# XHSC_HC32L19X register map
Vendor: XHSC Co.Ltd; Series: ARMCM0P; File version: 1.2
CPU: CM0 r0p0, little endian, no MPU, no FPU, 3 interrupt priority bits
Registers are 32-bit, read-write, reset 0x0 unless marked. A register's access mark holds for its fields unless they carry their own. Offsets are from the block's base; [hi:lo] are bit positions; {n}, {i} and the like mark numbered series; 'fields as' and 'values as' point back to an identical list.

## AES
Base 0x40021400
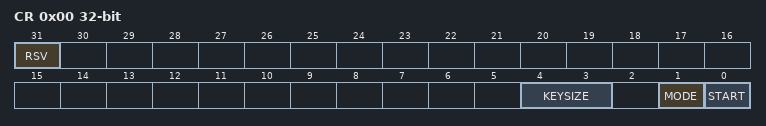
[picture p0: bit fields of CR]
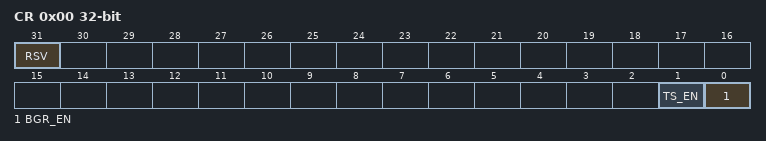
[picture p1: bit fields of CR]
0x00 CR (reset mask 0x3)
  [31] RSV, [4:3] KEYSIZE, [1] MODE, [0] START
0x10 DATA0
{0x10+4i} DATA{i} (i=1..3)
  [31:0] DATA0
0x20 KEY0
{0x20+4i} KEY{i} (i=1..7)
  [31:0] KEY0

## BGR
Base 0x40002400; alternate view of ADC
0x00 CR (reset mask 0x3)
  [31] RSV, [1] TS_EN, [0] BGR_EN

## CLK_TRIM
Base 0x40001800
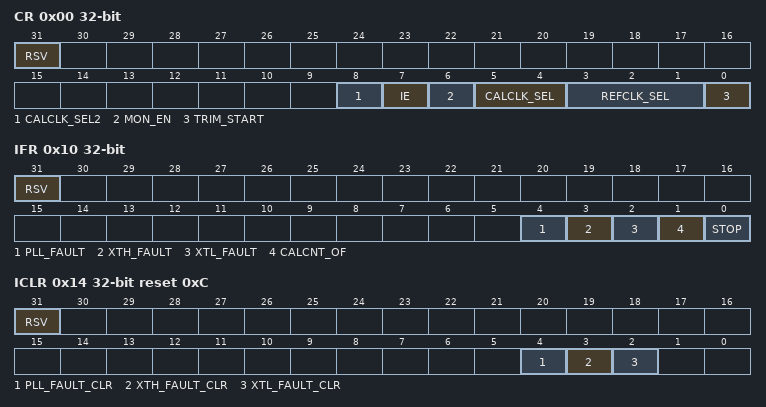
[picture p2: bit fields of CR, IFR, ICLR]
0x00 CR (reset mask 0xFF)
  [31] RSV, [8] CALCLK_SEL2, [7] IE, [6] MON_EN, [5:4] CALCLK_SEL, [3:1] REFCLK_SEL, [0] TRIM_START
0x04 REFCON
  [31:0] RCNTVAL
0x08 REFCNT ro
0x0C CALCNT ro
0x10 IFR ro (reset mask 0xF)
  [31] RSV, [4] PLL_FAULT, [3] XTH_FAULT, [2] XTL_FAULT, [1] CALCNT_OF, [0] STOP
0x14 ICLR reset 0xC (reset mask 0xC)
  [31] RSV, [4] PLL_FAULT_CLR, [3] XTH_FAULT_CLR, [2] XTL_FAULT_CLR
0x18 CALCON reset 0xFFFFFFFF
  [31:0] CCNTVAL

## CRC
Base 0x40020900
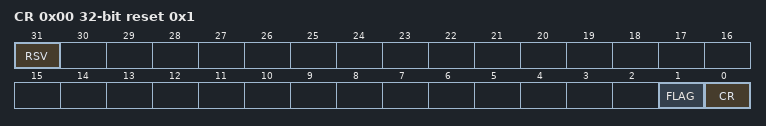
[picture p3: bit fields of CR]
0x00 CR reset 0x1 (reset mask 0x3)
  [31] RSV ro, [1] FLAG ro, [0] CR
0x04 RESULT
0x80 DATA wo

## DAC
Base 0x40002500
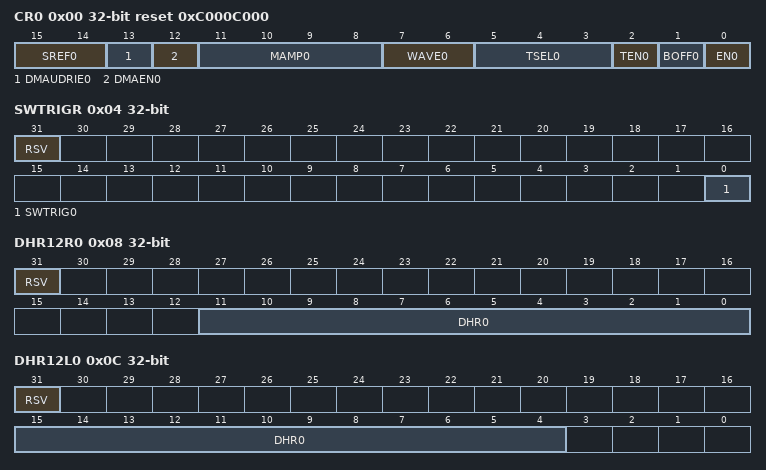
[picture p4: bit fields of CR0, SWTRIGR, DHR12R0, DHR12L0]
0x00 CR0 reset 0xC000C000
  [15:14] SREF0, [13] DMAUDRIE0, [12] DMAEN0, [11:8] MAMP0, [7:6] WAVE0, [5:3] TSEL0, [2] TEN0, [1] BOFF0, [0] EN0
0x04 SWTRIGR wo (reset mask 0x3)
  [31] RSV rw, [0] SWTRIG0
0x08 DHR12R0 (reset mask 0xFFF)
  [31] RSV, [11:0] DHR0
0x0C DHR12L0 (reset mask 0xFFF0)
  [31] RSV, [15:4] DHR0
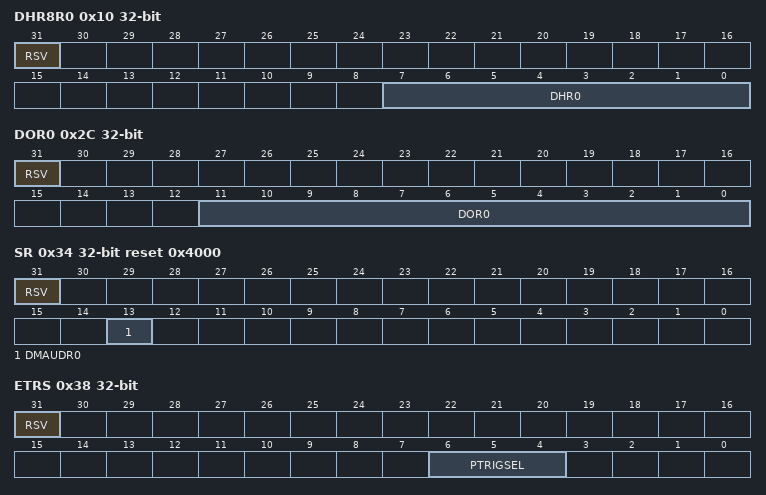
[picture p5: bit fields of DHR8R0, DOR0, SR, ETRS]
0x10 DHR8R0 (reset mask 0xFF)
  [31] RSV, [7:0] DHR0
0x2C DOR0 ro (reset mask 0xFFF)
  [31] RSV rw, [11:0] DOR0
0x34 SR reset 0x4000 (reset mask 0x20002000)
  [31] RSV, [13] DMAUDR0
0x38 ETRS (reset mask 0x70)
  [31] RSV, [6:4] PTRIGSEL

## DEBUG_ACTIVE
Base 0x40002038
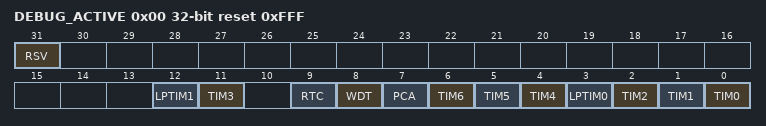
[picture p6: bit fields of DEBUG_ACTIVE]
0x00 DEBUG_ACTIVE reset 0xFFF (reset mask 0xFFF)
  [31] RSV, [12] LPTIM1, [11] TIM3, [9] RTC, [8] WDT, [7] PCA, [6] TIM6, [5] TIM5, [4] TIM4, [3] LPTIM0, [2] TIM2, [1] TIM1, [0] TIM0

## DMAC
Base 0x40021000
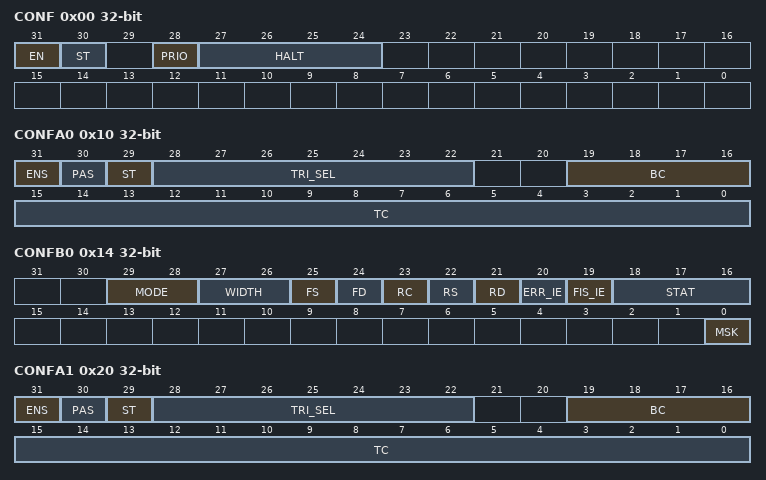
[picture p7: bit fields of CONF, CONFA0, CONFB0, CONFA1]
0x00 CONF
  [31] EN, [30] ST, [28] PRIO, [27:24] HALT
0x10 CONFA0 (reset mask 0xFF8FFFFF)
  [31] ENS, [30] PAS, [29] ST, [28:22] TRI_SEL, [19:16] BC, [15:0] TC
0x14 CONFB0
  [29:28] MODE, [27:26] WIDTH, [25] FS, [24] FD, [23] RC, [22] RS, [21] RD, [20] ERR_IE, [19] FIS_IE, [18:16] STAT, [0] MSK
0x18 SRCADR0
  [31:0] SRCADR
0x1C DSTADR0
  [31:0] DSTADR
0x20 CONFA1 (reset mask 0xFF8FFFFF)
  [31] ENS, [30] PAS, [29] ST, [28:22] TRI_SEL, [19:16] BC, [15:0] TC
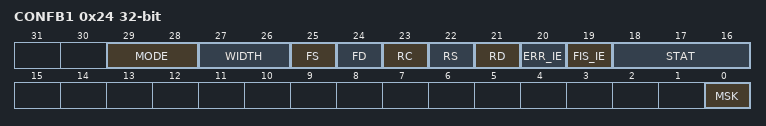
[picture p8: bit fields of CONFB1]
0x24 CONFB1
  fields as CONFB0
0x28 SRCADR1
  [31:0] SRCADR
0x2C DSTADR1
  [31:0] DSTADR

## FLASH
Base 0x40020000
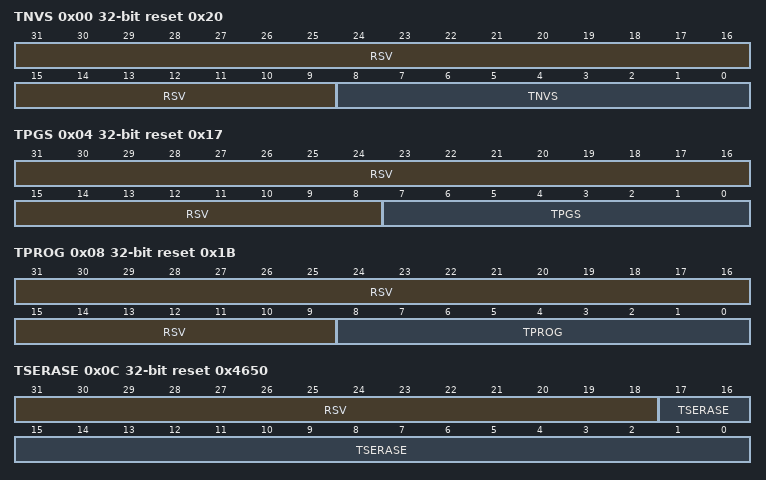
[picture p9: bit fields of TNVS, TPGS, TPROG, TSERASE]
0x00 TNVS reset 0x20 (reset mask 0x1FF)
  [31:9] RSV, [8:0] TNVS
0x04 TPGS reset 0x17 (reset mask 0xFF)
  [31:8] RSV, [7:0] TPGS
0x08 TPROG reset 0x1B (reset mask 0xFF)
  [31:9] RSV, [8:0] TPROG
0x0C TSERASE reset 0x4650 (reset mask 0x3FFFF)
  [31:18] RSV, [17:0] TSERASE
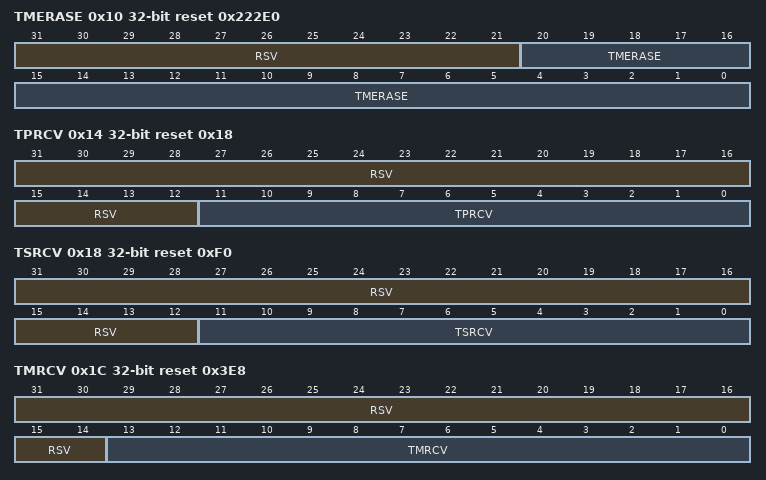
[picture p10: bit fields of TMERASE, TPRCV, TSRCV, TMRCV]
0x10 TMERASE reset 0x222E0 (reset mask 0x1FFFFF)
  [31:21] RSV, [20:0] TMERASE
0x14 TPRCV reset 0x18 (reset mask 0xFFF)
  [31:12] RSV, [11:0] TPRCV
0x18 TSRCV reset 0xF0 (reset mask 0xFFF)
  [31:12] RSV, [11:0] TSRCV
0x1C TMRCV reset 0x3E8 (reset mask 0x1FFF)
  [31:14] RSV, [13:0] TMRCV
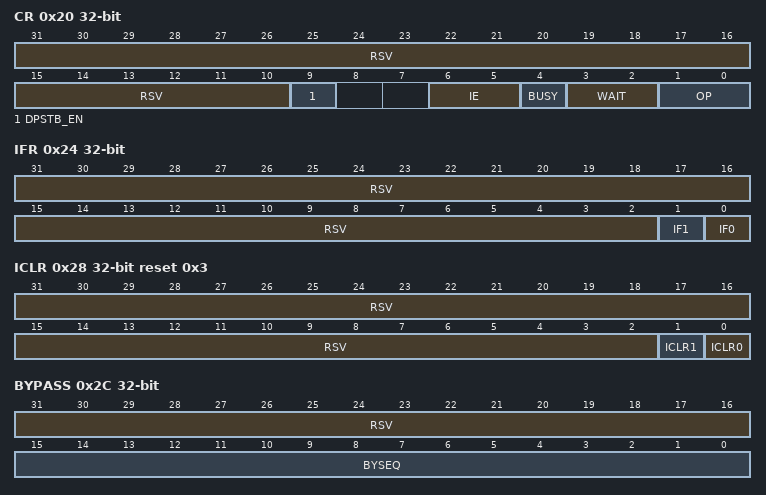
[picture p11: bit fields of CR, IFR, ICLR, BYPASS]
0x20 CR
  [31:10] RSV, [9] DPSTB_EN, [6:5] IE, [4] BUSY ro, [3:2] WAIT, [1:0] OP
0x24 IFR ro (reset mask 0x3)
  [31:2] RSV rw, [1] IF1, [0] IF0
0x28 ICLR wo reset 0x3
  [31:2] RSV rw, [1] ICLR1, [0] ICLR0
0x2C BYPASS wo (reset mask 0xFFFF)
  [31:16] RSV rw, [15:0] BYSEQ
0x30 SLOCK0
  [31:0] SLOCK
0x34 SLOCK1
  [31:0] SLOCK
0x40 SLOCK2
  [31:0] SLOCK
0x44 SLOCK3
  [31:0] SLOCK

## I2C0 — desc I2C
Base 0x40000400
Same registers: I2C1 0x40004400
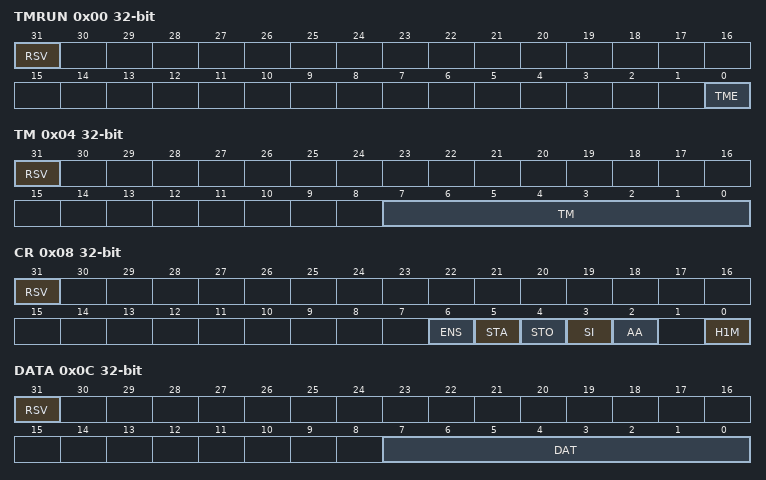
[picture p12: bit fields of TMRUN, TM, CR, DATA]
0x00 TMRUN (reset mask 0x1)
  [31] RSV, [0] TME
0x04 TM (reset mask 0xFF)
  [31] RSV, [7:0] TM
0x08 CR (reset mask 0x7D)
  [31] RSV, [6] ENS, [5] STA, [4] STO, [3] SI, [2] AA, [0] H1M
0x0C DATA (reset mask 0xFF)
  [31] RSV, [7:0] DAT
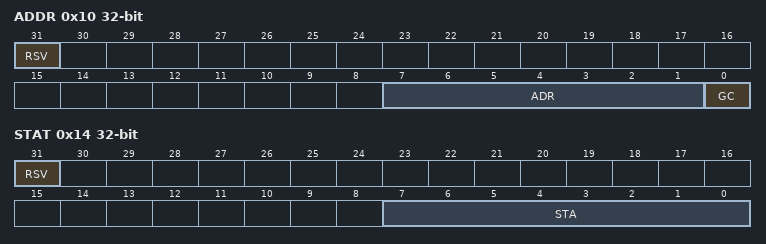
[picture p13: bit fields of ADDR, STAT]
0x10 ADDR (reset mask 0xFF)
  [31] RSV, [7:1] ADR, [0] GC
0x14 STAT ro (reset mask 0xFF)
  [31] RSV rw, [7:0] STA
